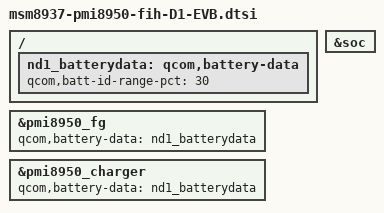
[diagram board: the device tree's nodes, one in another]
/*
 * Copyright (c) 2016, The Linux Foundation. All rights reserved.
 *
 * This program is free software; you can redistribute it and/or modify
 * it under the terms of the GNU General Public License version 2 and
 * only version 2 as published by the Free Software Foundation.
 *
 * This program is distributed in the hope that it will be useful,
 * but WITHOUT ANY WARRANTY; without even the implied warranty of
 * MERCHANTABILITY or FITNESS FOR A PARTICULAR PURPOSE.  See the
 * GNU General Public License for more details.
 */

#include "msm8937-pmi8950-fih-D1C-EVT.dtsi"
#include "msm8937-fih-D1-v0.dtsi"
//  add for d1 int_codec
#include "msm8937-audio-mtp-nd1.dtsi"

&soc {
};

/{
	/delete-node/ qcom,battery-data;
	nd1_batterydata: qcom,battery-data {
		qcom,batt-id-range-pct = <30>;
		#include "components/power/batterydata-nd1c_2900mAh_Coslight_39.dtsi"
		#include "components/power/batterydata-nd1c_2900mAh_SDI_68.dtsi"
		#include "components/power/batterydata-nd1c_2900mAh_SDI_100.dtsi"
		#include "components/power/batterydata-nd1c_2900mAh_Coslight_200.dtsi"
	};
};

&pmi8950_fg {
	qcom,battery-data = <&nd1_batterydata>;
};

&pmi8950_charger {
	qcom,battery-data = <&nd1_batterydata>;
};
